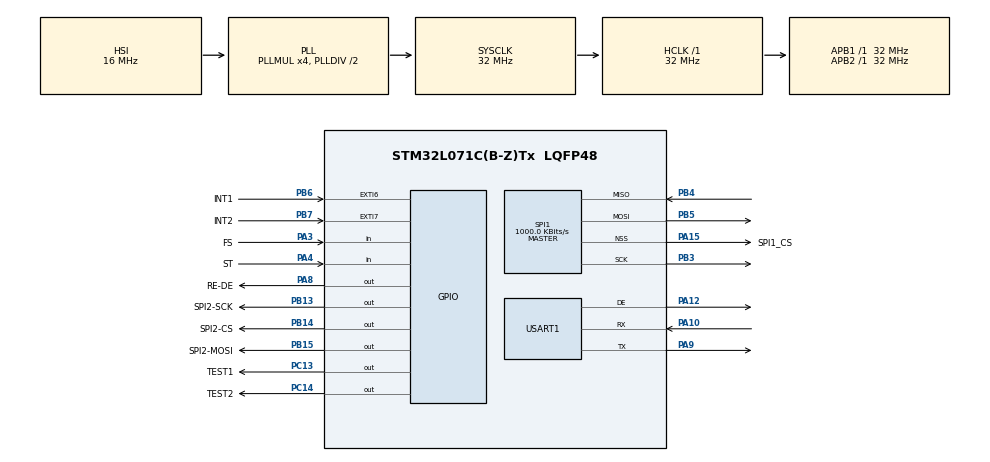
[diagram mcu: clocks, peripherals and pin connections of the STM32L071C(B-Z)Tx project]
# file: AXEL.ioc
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Mcu.Family=STM32L0
Mcu.Name=STM32L071C(B-Z)Tx
Mcu.Package=LQFP48
PA0.GPIO_Label=ADC-X
PA0.Signal=ADC_IN0
PA1.GPIO_Label=ADC-Y
PA1.Signal=ADC_IN1
PA10.Mode=Asynchronous
PA10.Signal=USART1_RX
PA12.Mode=Hardware Flow Control (RS485)
PA12.Signal=USART1_DE
PA13.Mode=Serial_Wire
PA13.Signal=SYS_SWDIO
PA14.Mode=Serial_Wire
PA14.Signal=SYS_SWCLK
PA15.GPIO_Label=SPI1_CS
PA15.Mode=NSS_Signal_Hard_Output
PA15.Signal=SPI1_NSS
PA2.GPIO_Label=ADC-Z
PA2.Signal=ADC_IN2
PA3.GPIO_Label=FS
PA3.Signal=GPIO_Input
PA4.GPIO_Label=ST
PA4.Signal=GPIO_Input
PA7.GPIO_Label=ADC-P
PA7.Signal=ADC_IN7
PA8.GPIO_Label=RE-DE
PA8.Signal=GPIO_Output
PA9.Mode=Asynchronous
PA9.Signal=USART1_TX
PB13.GPIO_Label=SPI2-SCK
PB13.Signal=GPIO_Output
PB14.GPIO_Label=SPI2-CS
PB14.Signal=GPIO_Output
PB15.GPIO_Label=SPI2-MOSI
PB15.Signal=GPIO_Output
PB3.Mode=Full_Duplex_Master
PB3.Signal=SPI1_SCK
PB4.Mode=Full_Duplex_Master
PB4.Signal=SPI1_MISO
PB5.Mode=Full_Duplex_Master
PB5.Signal=SPI1_MOSI
PB6.GPIO_Label=INT1
PB6.Signal=GPXTI6
PB7.GPIO_Label=INT2
PB7.Signal=GPXTI7
PC13.GPIO_Label=TEST1
PC13.Signal=GPIO_Output
PC14-OSC32_IN.GPIO_Label=TEST2
PC14-OSC32_IN.Signal=GPIO_Output
PH0-OSC_IN.Mode=HSE-External-Oscillator
PH0-OSC_IN.Signal=RCC_OSC_IN
PH1-OSC_OUT.Mode=HSE-External-Oscillator
PH1-OSC_OUT.Signal=RCC_OSC_OUT
ProjectManager.HeapSize=0x200
ProjectManager.StackSize=0x400
ProjectManager.TargetToolchain=EWARM V8
RCC.AHBFreq_Value=32000000
RCC.APB1Freq_Value=32000000
RCC.APB1TimFreq_Value=32000000
RCC.APB2Freq_Value=32000000
RCC.APB2TimFreq_Value=32000000
RCC.HCLKFreq_Value=32000000
RCC.HSE_VALUE=16000000
RCC.HSI16_VALUE=16000000
RCC.HSI_VALUE=16000000
RCC.LSE_VALUE=32768
RCC.MSI_VALUE=2097000
RCC.PLLMUL=RCC_PLLMUL_4
RCC.SYSCLKFreq_VALUE=32000000
RCC.SYSCLKSource=RCC_SYSCLKSOURCE_PLLCLK
RCC.VCOOutputFreq_Value=64000000
SPI1.BaudRatePrescaler=SPI_BAUDRATEPRESCALER_32
SPI1.CLKPhase=SPI_PHASE_2EDGE
SPI1.CLKPolarity=SPI_POLARITY_HIGH
SPI1.CalculateBaudRate=1000.0 KBits/s
SPI1.DataSize=SPI_DATASIZE_8BIT
SPI1.Direction=SPI_DIRECTION_2LINES
SPI1.Mode=SPI_MODE_MASTER
SPI1.TIMode=SPI_TIMODE_DISABLE
SPI1.VirtualNSS=VM_NSSHARD
SPI1.VirtualType=VM_MASTER
USART1.VirtualMode-Asynchronous=VM_ASYNC
USART1.VirtualMode-Hardware\ Flow\ Control\ (RS485)=VM_ASYNC
board=custom

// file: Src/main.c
/* USER CODE BEGIN Header */
/**
  ******************************************************************************
  * @file           : main.c
  * @brief          : Main program body
  ******************************************************************************
  ** This notice applies to any and all portions of this file
  * that are not between comment pairs USER CODE BEGIN and
  * USER CODE END. Other portions of this file, whether
  * inserted by the user or by software development tools
  * are owned by their respective copyright owners.
  *
  * COPYRIGHT(c) 2019 STMicroelectronics
  *
  * Redistribution and use in source and binary forms, with or without modification,
  * are permitted provided that the following conditions are met:
  *   1. Redistributions of source code must retain the above copyright notice,
  *      this list of conditions and the following disclaimer.
  *   2. Redistributions in binary form must reproduce the above copyright notice,
  *      this list of conditions and the following disclaimer in the documentation
  *      and/or other materials provided with the distribution.
  *   3. Neither the name of STMicroelectronics nor the names of its contributors
  *      may be used to endorse or promote products derived from this software
  *      without specific prior written permission.
  *
  * THIS SOFTWARE IS PROVIDED BY THE COPYRIGHT HOLDERS AND CONTRIBUTORS "AS IS"
  * AND ANY EXPRESS OR IMPLIED WARRANTIES, INCLUDING, BUT NOT LIMITED TO, THE
  * IMPLIED WARRANTIES OF MERCHANTABILITY AND FITNESS FOR A PARTICULAR PURPOSE ARE
  * DISCLAIMED. IN NO EVENT SHALL THE COPYRIGHT HOLDER OR CONTRIBUTORS BE LIABLE
  * FOR ANY DIRECT, INDIRECT, INCIDENTAL, SPECIAL, EXEMPLARY, OR CONSEQUENTIAL
  * DAMAGES (INCLUDING, BUT NOT LIMITED TO, PROCUREMENT OF SUBSTITUTE GOODS OR
  * SERVICES; LOSS OF USE, DATA, OR PROFITS; OR BUSINESS INTERRUPTION) HOWEVER
  * CAUSED AND ON ANY THEORY OF LIABILITY, WHETHER IN CONTRACT, STRICT LIABILITY,
  * OR TORT (INCLUDING NEGLIGENCE OR OTHERWISE) ARISING IN ANY WAY OUT OF THE USE
  * OF THIS SOFTWARE, EVEN IF ADVISED OF THE POSSIBILITY OF SUCH DAMAGE.
  *
  ******************************************************************************
  */
/* USER CODE END Header */

#include "main.h"
#include "spi.h"
#include "usart.h"
#include "gpio.h"

/* USER CODE BEGIN Includes */
#include "stdint.h"
/* USER CODE END Includes */

void SystemClock_Config(void);
/* USER CODE BEGIN PFP */
int run(void);
/* USER CODE END PFP */

int main(void)
{

  /* MCU Configuration--------------------------------------------------------*/

  /* Reset of all peripherals, Initializes the Flash interface and the Systick. */
  HAL_Init();

  /* Configure the system clock */
  SystemClock_Config();

  /* Initialize all configured peripherals */
  MX_GPIO_Init();
  MX_USART1_UART_Init();
  MX_SPI1_Init();

  /* Infinite loop */
  /* USER CODE BEGIN WHILE */
  run();
  while (1)
  {
    /* USER CODE END WHILE */

  }
}

void SystemClock_Config(void)
{
  RCC_OscInitTypeDef RCC_OscInitStruct = {0};
  RCC_ClkInitTypeDef RCC_ClkInitStruct = {0};
  RCC_PeriphCLKInitTypeDef PeriphClkInit = {0};

  /**Configure the main internal regulator output voltage
  */
  __HAL_PWR_VOLTAGESCALING_CONFIG(PWR_REGULATOR_VOLTAGE_SCALE1);
  /**Initializes the CPU, AHB and APB busses clocks
  */
  RCC_OscInitStruct.OscillatorType = RCC_OSCILLATORTYPE_HSI;
  RCC_OscInitStruct.HSIState = RCC_HSI_ON;
  RCC_OscInitStruct.HSICalibrationValue = RCC_HSICALIBRATION_DEFAULT;
  RCC_OscInitStruct.PLL.PLLState = RCC_PLL_ON;
  RCC_OscInitStruct.PLL.PLLSource = RCC_PLLSOURCE_HSI;
  RCC_OscInitStruct.PLL.PLLMUL = RCC_PLLMUL_4;
  RCC_OscInitStruct.PLL.PLLDIV = RCC_PLLDIV_2;
  if (HAL_RCC_OscConfig(&RCC_OscInitStruct) != HAL_OK)
  {
    Error_Handler();
  }
  /**Initializes the CPU, AHB and APB busses clocks
  */
  RCC_ClkInitStruct.ClockType = RCC_CLOCKTYPE_HCLK|RCC_CLOCKTYPE_SYSCLK
                              |RCC_CLOCKTYPE_PCLK1|RCC_CLOCKTYPE_PCLK2;
  RCC_ClkInitStruct.SYSCLKSource = RCC_SYSCLKSOURCE_PLLCLK;
  RCC_ClkInitStruct.AHBCLKDivider = RCC_SYSCLK_DIV1;
  RCC_ClkInitStruct.APB1CLKDivider = RCC_HCLK_DIV1;
  RCC_ClkInitStruct.APB2CLKDivider = RCC_HCLK_DIV1;

  if (HAL_RCC_ClockConfig(&RCC_ClkInitStruct, FLASH_LATENCY_1) != HAL_OK)
  {
    Error_Handler();
  }
  PeriphClkInit.PeriphClockSelection = RCC_PERIPHCLK_USART1;
  PeriphClkInit.Usart1ClockSelection = RCC_USART1CLKSOURCE_PCLK2;
  if (HAL_RCCEx_PeriphCLKConfig(&PeriphClkInit) != HAL_OK)
  {
    Error_Handler();
  }
}

void Error_Handler(void)
{
}

/************************ (C) COPYRIGHT STMicroelectronics *****END OF FILE****/
